# SPC1068 register map
File version: 20180100_70611510
CPU: CM3 r2p1, little endian, MPU, no FPU, 4 interrupt priority bits
Registers are 32-bit, read-write, reset 0x0 unless marked. A register's access mark holds for its fields unless they carry their own. Offsets are from the block's base; [hi:lo] are bit positions; {n}, {i} and the like mark numbered series; 'fields as' and 'values as' point back to an identical list.

## QSPI — NOEN
Base 0x40009000
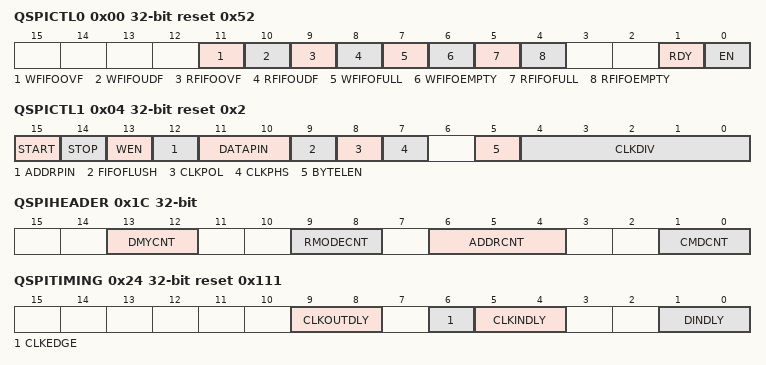
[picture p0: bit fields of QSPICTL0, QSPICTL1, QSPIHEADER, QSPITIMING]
0x00 QSPICTL0 reset 0x52 — Serial Interface Control Register 0
  [11] WFIFOOVF ro — Write FIFO Overflow
    0=NOT_OCCUR (Write FIFO is not overflowed); 1=OCCUR (Write FIFO is overflowed)
  [10] WFIFOUDF ro — Write FIFO Underflow
    0=NOT_OCCUR (Write FIFO is not underflowed); 1=OCCUR (Write FIFO is underflowed)
  [9] RFIFOOVF ro — Read FIFO Overflow
    0=NOT_OCCUR (Read FIFO is not overflowed); 1=OCCUR (Read FIFO is overflowed)
  [8] RFIFOUDF ro — Read FIFO Underflow
    0=NOT_OCCUR (Read FIFO is not underflowed); 1=OCCUR (Read FIFO is underflowed)
  [7] WFIFOFULL ro — Write FIFO Full
    0=NOT_OCCUR (Write FIFO is not filled); 1=OCCUR (Write FIFO is filled)
  [6] WFIFOEMPTY ro — Write FIFO Empty
    0=NOT_OCCUR (Write FIFO is not emptied); 1=OCCUR (Write FIFO is emptied)
  [5] RFIFOFULL ro — Read FIFO Full
    0=NOT_OCCUR (Read FIFO is not filled); 1=OCCUR (Read FIFO is filled)
  [4] RFIFOEMPTY ro — Read FIFO Empty
    0=NOT_OCCUR (Read FIFO is not emptied); 1=OCCUR (Read FIFO is emptied)
  [1] RDY ro — Serial Interface Transfer Ready
    0=TRANSFER_BUSY (Serial Interface is currently transferring data); 1=TRANSFER_READY (Serial Interface is ready for a new transfer)
  [0] EN — Serial Select Enable
    0=DISABLE (Serial select is de-activated); 1=ENABLE (Serial select is activated)
0x04 QSPICTL1 reset 0x2 — Serial Interface Control Register 1
  [15] START — Transfer Start. This bit starts the serial interface I/O transfer. For read transfers, WEN (R04[13]) = 0, the hardware resets this bit to 0 when the number of bytes indicated in QSPIDINCNT(R20h) register have been read in from the interface. For write transfers, WEN (R04[13]) = 1, firmware sets. STOP (R04h [14]) = 1 when all data have been written to the WFIFO and WFIFOEMPTY (R00h [6]) = 1. Hardware resets this bit to 0 when all data have been written out the interface.
    0=TRANSFER_COMPLETED (Transfer has completed); 1=TRANSFER_START (Transfer has started)
  [14] STOP — Transfer Stop. This bit stops the serial interface I/O transfer. The transfer stops at either a 1-byte or 4-byte boundary, depending on the setting of BYTELEN (R04h [5]). Once the byte boundary is reached, the hardware resets START (R04h [15]) to 0. Hardware resets this bit to 0 after START has been reset.
    0=TRANSFER_CONTINUE (Continue current transfer); 1=TRANSFER_STOP (Stop current transfer)
  [13] WEN — Write Enable
    0=READ (Read data from the serial interface); 1=WRITE (Write data to the serial interface)
  [12] ADDRPIN — Address Transfer Pin. Number of pins used for transferring the content of the Addr (R14h) register.
    0=1_PIN (Use one serial interface pin); 1=NUM_DATA_PIN (Use the number of pins as indicated in DATAPIN (R04h [11:10]))
  [11:10] DATAPIN — Data Transfer Pin. Number of pins used for transferring the non-command and nonaddress portions of each serial interface I/O transfer.
    0=1_PIN (Use 1 serial interface pin (use in single mode)); 1=2_PIN (Use 2 serial interface pins (use in dual mode)); 2=3_PIN (Use 4 serial interface pins (use in quad mode))
  [9] FIFOFLUSH — Flush Read and Write FIFOs. This bit flushes the Read and Write FIFOs. The FIFOs are emptied after being flushed. Hardware resets this bit to 0 after flushing.
    0=NOT_FLUSH (Read and Write FIFOs are not flushed); 1=FLUSH (Read and Write FIFOs are flushed)
  [8] CLKPOL — Serial Interface Clock Polarity
    0=INACTIVE_LOW (Serial interface clock is low when inactive); 1=INACTIVE_HIGH (Serial interface clock is high when inactive)
  [7] CLKPHS — Serial Interface Clock Phase
    0=MODE_0 (Data is latched at the rising edge of the serial interface clock when CLKPOL (R04h [8]) = 0, and at the falling edge of the serial interface clock when CLKPOL = 1); 1=MODE_1 (Data is latched at the falling edge of the serial interface clock when CLK_POL = 0, and at the rising edge of the serial interface clock when CLK_POL = 1)
  [5] BYTELEN — Byte Length. The number of bytes in each serial interface I/O transfer.
    0=1_BYTE; 1=4_BYTE (4 bytes)
  [4:0] CLKDIV — Serial Interface Clock Prescaler (from SPI clock)
    0=SPI clock/1; {v}=SPI clock/{v} (v=2..15); 24=SPI clock/16; 25=SPI clock/18; 26=SPI clock/20; 27=SPI clock/22; 28=SPI clock/24; 29=SPI clock/26; 30=SPI clock/28; 31=SPI clock/30
0x08 QSPIDOUT — Serial Interface Data Out Register
  [31:0] VAL — Serial Interface Data Out. Writing to this register stores the data in a 8X32 bit Write. FIFO. After the contents of the Instruction register (R10h), the Address register (R14h), the Read Mode register (R18h) and Dummy value are transferred out to the serial interface, the data in the Write FIFO is shifted out. The serial interface clock stops when a Write FIFO empty condition occurs, WFIFOEMPTY (R00h [6]) = 1. The clock restarts when Write FIFO is not empty, WFIFOEMPTY (R00h [6]) = 0. When BYTELEN (R04h [5]) = 0, bits [7:0] are shifted out with bit 7 shifted out first and bit 0 shifted out last. When BYTELEN (R04h [5]) = 1, bits [7:0] are shifted out (bit 7 shifted out first and bit 0 shifted out last), followed by bits [15:8] (bit 15 shifted out first and bit 8 shifted out last), then bits [23:16] (bit 23 shifted out first and bit 16 shifted out last) and finally bits [31:24] (bit 31 shifted out first and bit 24 shifted out last). Note: To avoid a Write FIFO overflow condition (WFIFOOVFW (R00h [11]) = 1), check WFIFOFULL (R00h [7]) is equal to 0 before writing to this register.
0x0C QSPIDIN ro — Serial Interface Data In Register
  [31:0] VAL — Serial Interface Data In. For read transfers, WEN (R04h [13]) = 0, data from the serial interface input pins are shifted in and stores in a 8X32 bit Read FIFO. The contents of the Read FIFO is read from this register. The serial interface clock stops when a Read FIFO full condition occurs, RFIFOFULL (R00h [5]) = 1. The clock restarts when Read FIFO is not full, RFIFOFULL (R00h [5]) = 0. When BYTELEN (R04h [5]) = 0, data is shifted into bits [7:0]. When BYTELEN (R04h [5]) = 1, data is shifted into bits [7:0] first, followed by bits [15:8], then bits [23:16] and finally bits [31:24]. Note: To avoid a Read FIFO underflow condition, RFIFOUDF (R00h [8]) = 1, check RFIFOEMPTY (R00h [4]) is equal to 0 before reading this register.
0x10 QSPICMD — Serial Interface Instruction Register
  [15:0] VAL — Serial Interface Instruction. After START (R04h [15]) is set to 1, the content of this register is shifted out to the serial interface. When CMDCNT (R1Ch [1:0]) = 0, the content of this register is not shifted out to the serial interface. When CMDCNT (R1Ch [1:0]) = 1, bits [7:0] are shifted out. When CMDCNT (R1Ch [1:0]) = 2, bits [15:8] are shifted out first, followed by bits [7:0].
0x14 QSPIADDR — Serial Interface Address Register
  [31:0] VAL — Serial Interface Address. After QSPICMD (R10h) is shifted out, the content of this register is shifted out to the serial interface. When ADDRCNT (R1Ch [6:4]) = 0, the content of this register is not shifted out to the serial interface. When ADDRCNT (R1Ch [6:4]) = 1, bits [7:0] are shifted out. When ADDRCNT (R1Ch [6:4]) = 2, bits [15:8] are shifted out first, followed by bits [7:0]. When ADDRCNT (R1Ch [6:4]) = 3, bits [23:16] are shifted out first, followed by bits [15:8], then bits [7:0]. When ADDRCNT (R1Ch [6:4]) = 4, bits [31:24] are shifted out first, followed by bits [23:16], then bits [15:8] and finally bits [7:0].
0x18 QSPIRMODE — Serial Interface Read Mode Register
  [15:0] VAL — Serial Interface Read Mode. After QSPIADDR(R14h) is shifted out, the content of this register is shifted out to the serial interface. When RMODECNT (R1Ch [9:8]) = 0, the content of this register is not shifted out to the serial interface. When RMODECNT (R1Ch [9:8]) = 1, bits [7:0] are shifted out. When RMODECNT (R1Ch [9:8]) = 2, bits [15:8] are shifted out first, followed by bits [7:0].
0x1C QSPIHEADER — Serial Interface Header Register
  [13:12] DMYCNT — Dummy Count. Number of bytes to shift out to the serial interface after the content of QSPIRMODE (R18h) register is shifted out. Note: The value being shifted out is 0.
    0=0_BYTE; 1=1_BYTE; 2=2_BYTE (2 bytes); 3=3_BYTE (3 bytes)
  [9:8] RMODECNT — Read Mode Count. Number of bytes in QSPIRMODE (R18h) register to shift out to the serial interface.
    0=0_BYTE; 1=1_BYTE; 2=2_BYTE (2 bytes)
  [6:4] ADDRCNT — Address Count. Number of bytes in QSPIADDR (R14h) register to shift out to the serial interface.
    0=0_BYTE; 1=1_BYTE; 2=2_BYTE (2 bytes); 3=3_BYTE (3 bytes); 4=4_BYTE (4 bytes)
  [1:0] CMDCNT — Instruction Count. Number of bytes in QSPICMD (R10h) register to shift out to the serial interface.
    0=0_BYTE; 1=1_BYTE; 2=2_BYTE (2 bytes)
0x20 QSPIDINCNT — Serial Interface Data In Count Register
  [19:0] VAL — Serial Interface Data In Count. For read transfers, WEN (R04h [13]) = 0, this register indicates the number of bytes of data to shift in from the serial interface and stores in the 8X32 bit Read FIFO. When this register is set to 0, data is shifted in continuously until STOP (R04h [14]) bit is set to 1 by firmware.
0x24 QSPITIMING reset 0x111 — Serial Interface Timing Register
  [9:8] CLKOUTDLY — Serial Interface Clock Out Delay. Programmable delay added to the serial interface output clock to adjust the timing.
    0=NO_DELAY; 1=0dot2_NS_DELAY (Add 0.2 ns delay); 2=0dot4_NS_DELAY (Add 0.4 ns delay); 3=0dot6_NS_DELAY (Add 0.6 ns delay)
  [6] CLKEDGE — Serial Interface Capture Clock Edge. Capture serial interface input data on either the rising or falling edge of the serial interface clock. This bit is used to allow more time to capture the input data. When CLKPOL (R04h [8]) = 0 and CLKPHA (R04h [7]) = 1, capture input data on the falling edge of the serial interface clock. When CLKPOL (R04h [8]) = 1 and CLKPHA (R04h [7]) = 0, capture input data on the falling edge of the serial interface clock. When CLKPOL (R04h [8]) = 1 and CLKPHA (R04h [7]) = 1, capture input data on the rising edge of the serial interface clock. When CLKPOL (R04h [8]) = 1 and CLKPHA (R04h [7]) = 0, capture input data on the rising edge of the serial interface clock. Note: When CLKPHA (R04h [7]) = 1, this bit must be set to 0.
    0=MODE_0 (When CLKPOL (R04h [8]) = 0 and CLKPHA (R04h[7]) = 0, capture input data on rising edge of the serial interface clock.); 1=MODE_1 (When CLK_POL (R04h [8]) = 0 and CLK_PHA (R04h[7]) = 0, capture input data on the falling edge of the serial interface clock.)
  [5:4] CLKINDLY — Serial Interface Clock In Delay. Programmable delay added to the serial interface input data capture clock.
    values as CLKOUTDLY
  [1:0] DINDLY — Serial Interface Data Input Delay. Delay the transfer of captured serial input data to the read register.
    0=NO_DELAY; 1=1_CLK_DELAY (1 serial interface clock delay); 2=2_CLK_DELAY (2 serial interface clock delay)
0x28 QSPICTL2 reset 0x1100 — Serial Interface Control Register 2
  [0] SWRST — Soft Reset. Allows firmware to reset the hardware. Note: After setting this bit to 1, firmware has to reset this bit to 0 before starting any transfer
    0=NOT_RESET (Hardware is not in reset); 1=RESET (Hardware is in reset. Mannully set to 0 for reset.)
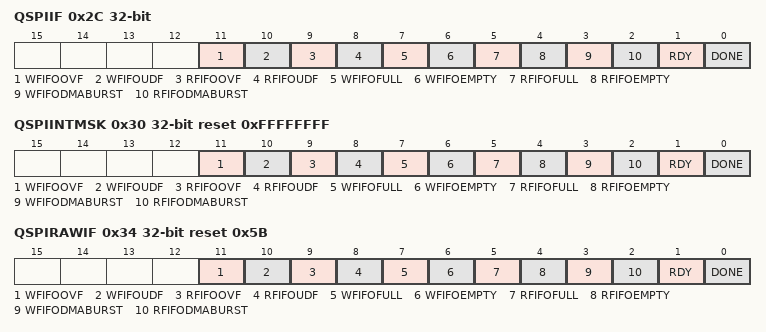
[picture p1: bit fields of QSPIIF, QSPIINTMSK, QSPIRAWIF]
0x2C QSPIIF ro — Serial Interface Interrupt Flag Register
  [11] WFIFOOVF — Write FIFO Overflow Interrupt Flag
    0=NOT_OCCUR (Write FIFO is not overflowed after masking); 1=OCCUR (Write FIFO is overflowed after masking)
  [10] WFIFOUDF — Write FIFO Underflow Interrupt Flag
    0=NOT_OCCUR (Write FIFO is not underflowed after masking); 1=OCCUR (Write FIFO is underflowed after masking)
  [9] RFIFOOVF — Read FIFO Overflow Interrupt Flag
    0=NOT_OCCUR (Read FIFO is not overflowed after masking); 1=OCCUR (Read FIFO is overflowed after masking)
  [8] RFIFOUDF — Read FIFO Underflow Interrupt Flag
    0=NOT_OCCUR (Read FIFO is not underflowed after masking); 1=OCCUR (Read FIFO is underflowed after masking)
  [7] WFIFOFULL — Write FIFO Full Interrupt Flag
    0=NOT_OCCUR (Write FIFO is not filled after masking); 1=OCCUR (Write FIFO is filled after masking)
  [6] WFIFOEMPTY — Write FIFO Empty Interrupt Flag
    0=NOT_OCCUR (Write FIFO is not emptied after masking); 1=OCCUR (Write FIFO is emptied after masking)
  [5] RFIFOFULL — Read FIFO Full Interrupt Flag
    0=NOT_OCCUR (Read FIFO is not filled after masking); 1=OCCUR (Read FIFO is filled after masking)
  [4] RFIFOEMPTY — Read FIFO Empty Interrupt Flag
    0=NOT_OCCUR (Read FIFO is not emptied after masking); 1=OCCUR (Read FIFO is empty after masking)
  [3] WFIFODMABURST — Write FIFO DMA burst Interrupt Flag
    0=NOT_OCCUR (Number of unused entries in the Write FIFO is less than DMAWBURST (R28h [13:12]) after masking); 1=OCCUR (Number of unused entries in the Write FIFO is greater than or equal to DMAWBURST (R28h [13:12]) after masking)
  [2] RFIFODMABURST — Read FIFO DMA Burst Interrupt Flag
    0=NOT_OCCUR (Number of available data in the Read FIFO is less than DMARBURST (R28h [9:8]) after masking); 1=OCCUR (Number of available data in the Read FIFO is greater than or equal to DMARBURST (R28h [9:8]) after masking)
  [1] RDY — Serial Interface Transfer Ready Interrupt Flag
    0=NOT_OCCUR (Serial interface is currently transferring data after masking); 1=OCCUR (Serial interface is ready for a new transfer after masking)
  [0] DONE — Transfer Done Interrupt Flag
    0=NOT_OCCUR (Transfer has not completed after masking); 1=OCCUR (Transfer has completed after masking)
0x30 QSPIINTMSK reset 0xFFFFFFFF — Serial Interface Interrupt Mask Register
  [11] WFIFOOVF — Write FIFO Overflow Interrupt Mask
    0=UNMASK (Write FIFO overflow interrupt is not masked); 1=MASK (Write FIFO overflow interrupt is masked)
  [10] WFIFOUDF — Write FIFO Underflow Interrupt Mask
    0=UNMASK (Write FIFO underflow interrupt is not masked); 1=MASK (Write FIFO underflow interrupt is masked)
  [9] RFIFOOVF — Read FIFO Overflow Interrupt Mask
    0=UNMASK (Read FIFO overflow interrupt is not masked); 1=MASK (Read FIFO overflow interrupt is masked)
  [8] RFIFOUDF — Read FIFO Underflow Interrupt Mask
    0=UNMASK (Read FIFO underflow interrupt is not masked); 1=MASK (Read FIFO underflow interrupt is masked)
  [7] WFIFOFULL — Write FIFO Full Interrupt Mask
    0=UNMASK (Write FIFO full interrupt is not masked); 1=MASK (Write FIFO full interrupt is masked)
  [6] WFIFOEMPTY — Write FIFO Empty Interrupt Mask
    0=UNMASK (Write FIFO empty interrupt is not masked); 1=MASK (Write FIFO empty interrupt is masked)
  [5] RFIFOFULL — Read FIFO Full Interrupt Mask
    0=UNMASK (Read FIFO full interrupt is not masked); 1=MASK (Read FIFO full interrupt is masked)
  [4] RFIFOEMPTY — Read FIFO Empty Interrupt Mask
    0=UNMASK (Read FIFO empty interrupt is not masked); 1=MASK (Read FIFO empty interrupt is masked)
  [3] WFIFODMABURST — Write FIFO DMA Burst Interrupt Mask
    0=UNMASK (Write FIFO DMA burst interrupt is not masked); 1=MASK (Write FIFO DMA burst interrupt is masked)
  [2] RFIFODMABURST — Read FIFO DMA Burst Interrupt Mask
    0=UNMASK (Read FIFO DMA burst interrupt is not masked); 1=MASK (Read FIFO DMA burst interrupt is masked)
  [1] RDY — Serial Interface Transfer Ready Mask
    0=UNMASK (Transfer ready interrupt is not masked); 1=MASK (Transfer ready interrupt is masked)
  [0] DONE — Transfer Done Interrupt Mask
    0=UNMASK (Transfer done interrupt is not masked); 1=MASK (Transfer done interrupt is masked)
0x34 QSPIRAWIF ro reset 0x5B — Serial Interface Interrupt Raw Flag Register
  [11] WFIFOOVF — Write FIFO Overflow Interrupt Raw
    0=NOT_OCCUR (Write FIFO is not overflowed before masking); 1=OCCUR (Write FIFO is overflowed before masking)
  [10] WFIFOUDF — Write FIFO Underflow Interrupt Raw
    0=NOT_OCCUR (Write FIFO is not underflowed before masking); 1=OCCUR (Write FIFO is underflowed before masking)
  [9] RFIFOOVF — Read FIFO Overflow Interrupt Raw
    0=NOT_OCCUR (Read FIFO is not overflowed before masking); 1=OCCUR (Read FIFO is overflowed before masking)
  [8] RFIFOUDF — Read FIFO Underflow Interrupt Raw
    0=NOT_OCCUR (Read FIFO is not underflowed before masking); 1=OCCUR (Read FIFO is underflowed before masking)
  [7] WFIFOFULL — Write FIFO Full Interrupt Raw
    0=NOT_OCCUR (Write FIFO is not filled before masking); 1=OCCUR (Write FIFO is filled before masking)
  [6] WFIFOEMPTY — Write FIFO Empty Interrupt Raw
    0=NOT_OCCUR (Write FIFO is not emptied before masking); 1=OCCUR (Write FIFO is emptied before masking)
  [5] RFIFOFULL — Read FIFO Full Interrupt Raw
    0=NOT_OCCUR (Read FIFO is not filled before masking); 1=OCCUR (Read FIFO is filled before masking)
  [4] RFIFOEMPTY — Read FIFO Empty Interrupt Raw
    0=NOT_OCCUR (Read FIFO is not emptied before masking); 1=OCCUR (Read FIFO is empty before masking)
  [3] WFIFODMABURST — Write FIFO DMA Burst Interrupt Raw
    0=NOT_OCCUR (Number of unused entries in the Write FIFO is less than DMAWBURST (R28h [13:12]) before masking); 1=OCCUR (Number of unused entries in the Write FIFO is greater than or equal to DMAWBURST (R28h [13:12]) before masking)
  [2] RFIFODMABURST — Read FIFO DMA Burst Interrupt Raw
    0=NOT_OCCUR (Number of available data in the Read FIFO is less than DMARBURST (R28h [9:8]) before masking); 1=OCCUR (Number of available data in the Read FIFO is greater than or equal to DMARBURST (R28h [9:8]) before masking)
  [1] RDY — Serial Interface Transfer Ready Raw
    0=NOT_OCCUR (Serial interface is currently transferring data before masking); 1=OCCUR (Serial interface is ready for a new transfer before masking)
  [0] DONE — Transfer Done Interrupt Raw
    0=NOT_OCCUR (Transfer has not completed before masking); 1=OCCUR (Transfer has completed before masking)
0x38 QSPIIC — Serial Interface Interrupt Clear Register
  [0] DONE — Transfer Done Interrupt Clear
    0=NO_EFFECT (Transfer done interrupt is not cleared); 1=CLEAR_FLAG (Transfer done interrupt is cleared)
